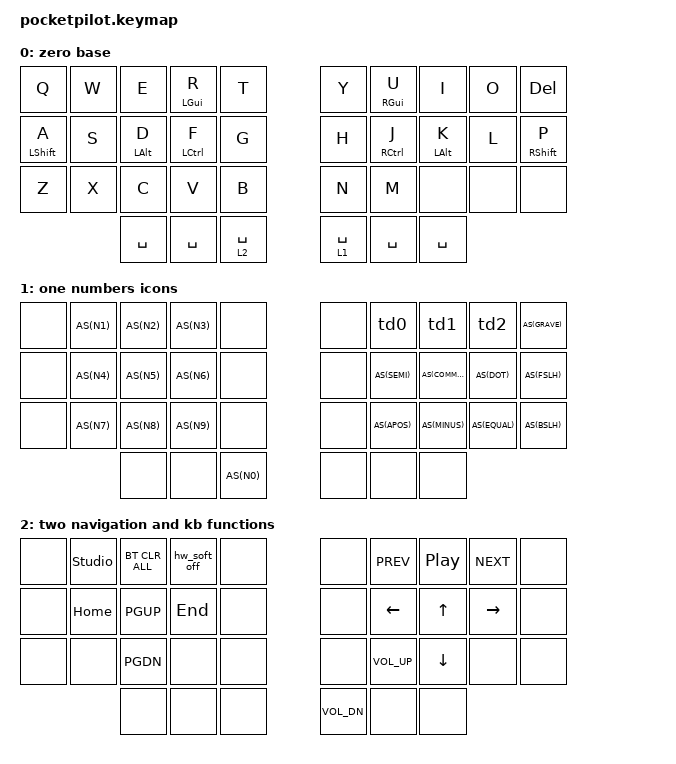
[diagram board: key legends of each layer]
#include <behaviors.dtsi>
#include <dt-bindings/zmk/keys.h>
#include <dt-bindings/zmk/bt.h>

#define ZMK_POINTING_DEFAULT_MOVE_VAL 1200  // default: 600

#include <dt-bindings/zmk/pointing.h>

#define AS(keycode) &as LS(keycode) keycode   

/ {
	behaviors {
		td0: tap_dance_0 {
			compatible = "zmk,behavior-tap-dance";
			#binding-cells = <0>;
			tapping-term-ms = <225>;
			bindings = <&kp LPAR>, <&kp RPAR>;
		};
		td1: tap_dance_1 {
			compatible = "zmk,behavior-tap-dance";
			#binding-cells = <0>;
			tapping-term-ms = <225>;
			bindings = <&kp LBRC>,<&kp RBRC>;
		};
		td2: tap_dance_2 {
			compatible = "zmk,behavior-tap-dance";
			#binding-cells = <0>;
			tapping-term-ms = <225>;
			bindings = <&kp LBKT>,<&kp RBKT>;
		};
		td3: tap_dance_3 {
			compatible = "zmk,behavior-tap-dance";
			#binding-cells = <0>;
			tapping-term-ms = <225>;
			bindings = <&kp TAB>,<&kp ESC>;
		};
		td4: tap_dance_4 {
			compatible = "zmk,behavior-tap-dance";
			#binding-cells = <0>;
			tapping-term-ms = <225>;
			bindings = <&kp C>,<&kp X>;
		};
		td5: tap_dance_5 {
			compatible = "zmk,behavior-tap-dance";
			#binding-cells = <0>;
			tapping-term-ms = <225>;
			bindings = <&kp F>,<&kp G>;
		};
		fmt: fast_mod_tap {
            		compatible = "zmk,behavior-hold-tap";
            		#binding-cells = <2>;
            		flavor = "hold-preferred";
            		tapping-term-ms = <125>;
            		bindings = <&kp>, <&kp>;
            		display-name = "Fast Mod-Tap";
        	};
		hml: home_row_mod_left {
            		compatible = "zmk,behavior-hold-tap";
            		#binding-cells = <2>;
            		flavor = "balanced";
            		require-prior-idle-ms = <100>;
            		tapping-term-ms = <250>;
            		quick-tap-ms = <175>;
            		bindings = <&kp>, <&kp>;
            		hold-trigger-key-positions = <3 4 5 10 11 12 13 16 17 19>; // List of keys on the right
            		hold-trigger-on-release;
        	};
        	hmr: home_row_mod_right {
            		compatible = "zmk,behavior-hold-tap";
            		#binding-cells = <2>;
            		flavor = "balanced";
            		require-prior-idle-ms = <100>;
            		tapping-term-ms = <250>;
            		quick-tap-ms = <175>;
            		bindings = <&kp>, <&kp>;
            		hold-trigger-key-positions = <0 1 2 6 7 8 9 14 15 18>; // List of keys on the left
            		hold-trigger-on-release;
        	};
		as: auto_shift {
            		compatible = "zmk,behavior-hold-tap";
            		#binding-cells = <2>;
            		tapping_term_ms = <175>;
            		quick_tap_ms = <0>;
            		flavor = "tap-preferred";
            		bindings = <&kp>, <&kp>;
        	};
		hw_soft_off: hw_soft_off {
            		compatible = "zmk,behavior-soft-off";
            		#binding-cells = <0>;
            		split-peripheral-off-on-press; // Turn peripheral off immediately for reliability
            		hold-time-ms = <1500>; // Only turn off if the key is held for 1.5 seconds or longer.
        	};
		mt: mod_tap {
            		tapping-term-ms = <250>;
        	};
		cmt: caps_mod_tap {
            		compatible = "zmk,behavior-hold-tap";
            		#binding-cells = <2>;
            		flavor = "hold-preferred";
            		tapping-term-ms = <250>;
            		bindings = <&caps_word>, <&none>;
            		display-name = "Caps Mod-Tap";
        	};
	};
	keymap {
		compatible = "zmk,keymap";
		one {
			display-name = "zero base";
			bindings = <
				&kp Q &kp W &kp E &hml LGUI R &kp T &kp Y &hmr RGUI U &kp I &kp O &kp DEL
				&hml LSHIFT A &kp S &hml LALT D &hml LCTRL F &kp G &kp H &hmr RCTRL J &hmr LALT K &kp L &hmr RSHIFT P
				&kp Z &kp X &kp C &kp V &kp B &kp N &kp M &none &none &none
				&kp SPACE &kp SPACE &lt 2 SPACE &lt 1 SPACE &kp SPACE &kp SPACE
			>;
		};
		two { display-name = "one numbers icons";
			bindings = <
				&none AS(N1) AS(N2) AS(N3) &none 	&none &td0 &td1 &td2 AS(GRAVE)
				&none AS(N4) AS(N5) AS(N6) &none   	&none AS(SEMI) AS(COMMA) AS(DOT) AS(FSLH)     
				&none AS(N7) AS(N8) AS(N9) &none   	&none AS(APOS) AS(MINUS) AS(EQUAL) AS(BSLH)    
					     &none &none AS(N0)   	&none &none &none
			>;
		};
		three { display-name = "two navigation and kb functions";
			bindings = <
				&none &studio_unlock &bt BT_CLR_ALL &hw_soft_off &none		&none &kp C_PREV &kp C_PP &kp C_NEXT &none
				&none &kp HOME &kp PGUP &kp END &none 				&none &kp LEFT &kp UP &kp RIGHT &none
				&none &none &kp PGDN &none &none  				&none &kp C_VOL_UP &kp DOWN &none &none
				            &none &none &none					&kp C_VOL_DN &none &none
			>;
		};
	};
};

/ {
	combos {
		compatible = "zmk,combos";

// keyboard functions
		combo_bt_one {
			timeout-ms = <50>;
			key-positions = <10 11 12 13>;
			bindings = <&bt BT_SEL 0>;
			layers = <0>;
		};
		combo_bt_two {
			timeout-ms = <50>;
			key-positions = <16 17 18 19>;
			bindings = <&bt BT_SEL 1>;
			layers = <0>;
		};
// mod keys
		combo_del {
			timeout-ms = <50>;
			key-positions = <10 11>;
			bindings = <&kp DEL>;
			layers = <0 1 2>;
		};
		combo_tab {
			timeout-ms = <50>;
			key-positions = <1 3>;
			bindings = <&kp TAB>;
		};
		combo_esc {
			timeout-ms = <50>;
			key-positions = <6 8>;
			bindings = <&kp ESC>;
		};
		combo_backspace {
			timeout-ms = <50>;
			key-positions = <18 19>;
			bindings = <&kp BSPC>;
			layers = <0 1 2>;
		};
		combo_enter {
			timeout-ms = <50>;
			key-positions = <13 16>;
			bindings = <&kp ENTER>;
			layers = <0 1 2>;
		};
		combo_capsword {
			timeout-ms = <50>;
			key-positions = <10 19>;
			bindings = <&caps_word>;
			layers = <0>;
		};

// arrow keys
		combo_up {
			timeout-ms = <50>;
			key-positions = <12 17>;
			bindings = <&kp UP>;
		};
		combo_left {
			timeout-ms = <50>;
			key-positions = <11 16>;
			bindings = <&kp LEFT>;
		};
		combo_down {
			timeout-ms = <50>;
			key-positions = <22 27>;
			bindings = <&kp DOWN>;
		};
		combo_right {
			timeout-ms = <50>;
			key-positions = <13 18>;
			bindings = <&kp RIGHT>;
		};
	};
};



